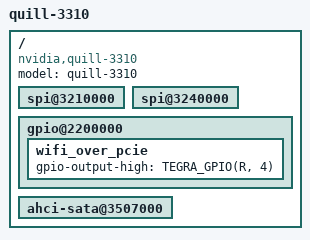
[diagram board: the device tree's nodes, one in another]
/*
 * tegra186-quill-common-p3310-1000-a00.dtsi: Quill common dtsi.
 *
 * Copyright (c) 2015, NVIDIA CORPORATION.  All rights reserved.
 *
 * This program is free software; you can redistribute it and/or modify
 * it under the terms of the GNU General Public License as published by
 * the Free Software Foundation; version 2 of the License.
 *
 * This program is distributed in the hope that it will be useful, but WITHOUT
 * ANY WARRANTY; without even the implied warranty of MERCHANTABILITY or
 * FITNESS FOR A PARTICULAR PURPOSE.  See the GNU General Public License for
 * more details.
 */

#include "tegra186-quill-common.dtsi"
#include "tegra186-quill-p3310-1000-a00-powermon.dtsi"

/ {
        model = "quill-3310";
        compatible = "nvidia,quill-3310", "nvidia,tegra186";

        #address-cells = <2>;
        #size-cells = <2>;

	spi@3210000 {
		status = "okay";
	};

	spi@3240000 {
		status = "okay";
	};

	gpio@2200000 {
		wifi_over_pcie {
			gpio-output-high = <TEGRA_GPIO(R, 4)>;
		};
	};

	ahci-sata@3507000 {
		status = "okay";
	};
};

